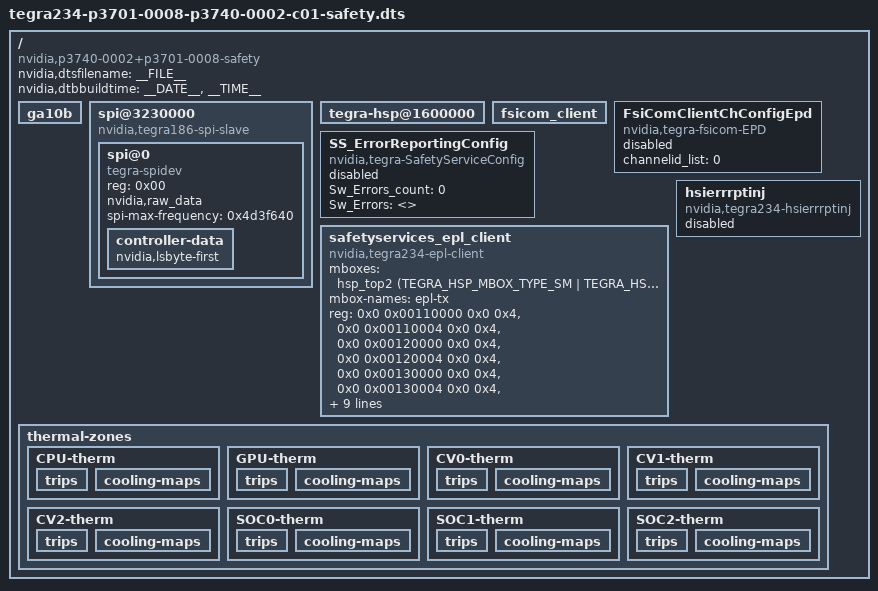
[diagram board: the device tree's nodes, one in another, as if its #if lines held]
/*
 * Top level DTS file for CVM:P3701-0002 and CVB:P3704-0002.
 *
 * Copyright (c) 2022-2023, NVIDIA CORPORATION.  All rights reserved.
 *
 * This program is free software; you can redistribute it and/or modify
 * it under the terms of the GNU General Public License as published by
 * the Free Software Foundation; version 2 of the License.
 *
 * This program is distributed in the hope that it will be useful, but WITHOUT
 * ANY WARRANTY; without even the implied warranty of MERCHANTABILITY or
 * FITNESS FOR A PARTICULAR PURPOSE.  See the GNU General Public License for
 * more details.
 */

/dts-v1/;
#include "tegra234-p3701-0008-p3740-0002-c01.dts"

/ {
	nvidia,dtsfilename = __FILE__;
	nvidia,dtbbuildtime = __DATE__, __TIME__;

	compatible = "nvidia,p3740-0002+p3701-0008-safety", "nvidia,tegra23x",
		      "nvidia,tegra234";

	/*
	 * Delete power-domains property for the gpu as it is always kept ON.
	 * This disables nvgpu railgating support.
	 */
	ga10b {
		/delete-property/ power-domains;
		status = "okay";
	};

	/*
	 * SPI3 instance is reserved for the CCPLEX-SMCU communications
	 * and can not be used for any other purposes.
	 */
	spi@3230000 {
		compatible = "nvidia,tegra186-spi-slave";
		status = "okay";

		spi@0 {
			compatible = "tegra-spidev";
			reg = <0x00>;
			nvidia,raw_data;
			spi-max-frequency = <0x4d3f640>;
			controller-data {
				nvidia,lsbyte-first;
			};
		};
	};

	/* This is hsp_top2 where fsi-ccplex comm happens in all below nodes */
	tegra-hsp@1600000 {
		status = "okay";
	};

	fsicom_client { /* Kernel driver on which FsiComIvc relies on */
		status = "okay";
	};

	/*
	 * The app is responsible to send runtime tunables from the node SS_ErrorReportingConfig
	 * for the FSI FW
	 */
	FsiComClientChConfigEpd {
                compatible = "nvidia,tegra-fsicom-EPD";
                status = "disabled";
                channelid_list = <0>;
        };

	SS_ErrorReportingConfig {
		compatible = "nvidia,tegra-SafetyServiceConfig";
		status = "disabled";
		/*Number of Sw Errors to be disabled*/
		Sw_Errors_count = <0>;
		/* List of SW errors to disable*/
		/*Entry should be<<reporter id> <mask>>*/
		/* Sample :<0x8000 0xFFFFFFFF>;*/
		/*If the Error code mask is 0xFFFFFFFF then all the error code from the reporter ID will be disabled*/
		Sw_Errors = <>;
	};

	safetyservices_epl_client { /* userspace app uses this driver to send error code */
		compatible = "nvidia,tegra234-epl-client";
		/*
		 * FSI FW version 1.1.1 uses HSP 1, while latest FSI FW version
		 * 1.5.4 onwards will be using HSP 0.
		 */
#if TEGRA_HSP_DT_VERSION >= DT_VERSION_2
		mboxes =
			<&hsp_top2 (TEGRA_HSP_MBOX_TYPE_SM | TEGRA_HSP_MBOX_TYPE_SM_128BIT) TEGRA_HSP_SM_TX(0)>;
#else
		mboxes =
			<&hsp_top2 TEGRA_HSP_MBOX_TYPE_SM_128BIT TEGRA_HSP_SM_TX(0)>;
#endif
		mbox-names = "epl-tx";

		reg = <0x0 0x00110000 0x0 0x4>,
			  <0x0 0x00110004 0x0 0x4>,
			  <0x0 0x00120000 0x0 0x4>,
			  <0x0 0x00120004 0x0 0x4>,
			  <0x0 0x00130000 0x0 0x4>,
			  <0x0 0x00130004 0x0 0x4>,
			  <0x0 0x00140000 0x0 0x4>,
			  <0x0 0x00140004 0x0 0x4>,
			  <0x0 0x00150000 0x0 0x4>,
			  <0x0 0x00150004 0x0 0x4>,
			  <0x0 0x024e0038 0x0 0x4>;

		/* Device driver's name for reporting errors via MISCREG_MISC_EC_ERR0_SW_ERR_CODE_0 */
		client-misc-sw-generic-err0 = "fsicom_client";
		/* Device driver's name for reporting errors via MISCREG_MISC_EC_ERR1_SW_ERR_CODE_0 */
		client-misc-sw-generic-err1 = "gk20b";
		/* Device driver's name for reporting errors via MISCREG_MISC_EC_ERR3_SW_ERR_CODE_0 */
		client-misc-sw-generic-err3 = "gk20d";
		/* Device driver's name for reporting errors via MISCREG_MISC_EC_ERR4_SW_ERR_CODE_0 */
		client-misc-sw-generic-err4 = "gk20e";

		status = "okay";
	};

	/*
	 * FIXME: there is no auto dtsi which enables this driver, and its mailbox
	 * shown in its yaml file overlaps with the fsicom_client driver. Keeping
	 * this disabled till it gets sorted out.
	 */
	hsierrrptinj {
		compatible = "nvidia,tegra234-hsierrrptinj";
		status = "disabled";
	};

	/*
	 * Disable thermal throttling features as FMON is enabled.
	 */
	/delete-node/ cpu-throttle-alert;
	/delete-node/ gpu-throttle-alert;
	/delete-node/ cv0-throttle-alert;
	/delete-node/ cv1-throttle-alert;
	/delete-node/ cv2-throttle-alert;
	/delete-node/ soc0-throttle-alert;
	/delete-node/ soc1-throttle-alert;
	/delete-node/ soc2-throttle-alert;

	thermal-zones {
		CPU-therm {
			trips {
				/delete-node/ cpu-sw-throttle;
			};

			cooling-maps {
				/delete-node/ map0;
				/delete-node/ user-alert-map0;
			};
		};

		GPU-therm {
			trips {
				/delete-node/ gpu-sw-throttle;
			};

			cooling-maps {
				/delete-node/ map0;
				/delete-node/ user-alert-map0;
			};
		};

		CV0-therm {
			trips {
				/delete-node/ cv0-sw-throttle;
			};

			cooling-maps {
				/delete-node/ map0;
				/delete-node/ user-alert-map0;
			};
		};

		CV1-therm {
			trips {
				/delete-node/ cv1-sw-throttle;
			};

			cooling-maps {
				/delete-node/ map0;
				/delete-node/ user-alert-map0;
			};
		};

		CV2-therm {
			trips {
				/delete-node/ cv2-sw-throttle;
			};

			cooling-maps {
				/delete-node/ map0;
				/delete-node/ user-alert-map0;
			};
		};

		SOC0-therm {
			trips {
				/delete-node/ soc0-sw-throttle;
			};

			cooling-maps {
				/delete-node/ map0;
				/delete-node/ user-alert-map0;
			};
		};

		SOC1-therm {
			trips {
				/delete-node/ soc1-sw-throttle;
			};

			cooling-maps {
				/delete-node/ map0;
				/delete-node/ user-alert-map0;
			};
		};

		SOC2-therm {
			trips {
				/delete-node/ soc2-sw-throttle;
			};

			cooling-maps {
				/delete-node/ map0;
				/delete-node/ user-alert-map0;
			};
		};
	};
};
